VERSION ""

NS_ :

BS_:

BU_: XXX

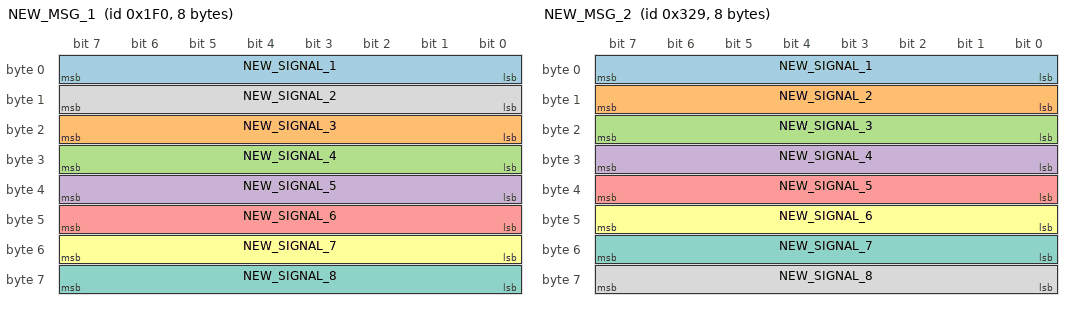
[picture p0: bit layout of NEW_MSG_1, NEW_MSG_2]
BO_ 496 NEW_MSG_1: 8 XXX
 SG_ NEW_SIGNAL_1 : 0|8@1+ (1,0) [0|255] "" XXX
 SG_ NEW_SIGNAL_3 : 23|8@0+ (1,0) [0|255] "" XXX
 SG_ NEW_SIGNAL_4 : 31|8@0+ (1,0) [0|255] "" XXX
 SG_ NEW_SIGNAL_5 : 39|8@0+ (1,0) [0|255] "" XXX
 SG_ NEW_SIGNAL_6 : 47|8@0+ (1,0) [0|255] "" XXX
 SG_ NEW_SIGNAL_7 : 55|8@0+ (1,0) [0|255] "" XXX
 SG_ NEW_SIGNAL_8 : 63|8@0+ (1,0) [0|255] "" XXX
 SG_ NEW_SIGNAL_2 : 15|8@0+ (1,0) [0|255] "" XXX

BO_ 809 NEW_MSG_2: 8 XXX
 SG_ NEW_SIGNAL_1 : 7|8@0+ (1,0) [0|255] "" XXX
 SG_ NEW_SIGNAL_2 : 15|8@0+ (1,0) [0|255] "" XXX
 SG_ NEW_SIGNAL_3 : 23|8@0+ (1,0) [0|255] "" XXX
 SG_ NEW_SIGNAL_4 : 31|8@0+ (1,0) [0|255] "" XXX
 SG_ NEW_SIGNAL_5 : 39|8@0+ (1,0) [0|255] "" XXX
 SG_ NEW_SIGNAL_6 : 47|8@0+ (1,0) [0|255] "" XXX
 SG_ NEW_SIGNAL_7 : 55|8@0+ (1,0) [0|255] "" XXX
 SG_ NEW_SIGNAL_8 : 63|8@0+ (1,0) [0|255] "" XXX

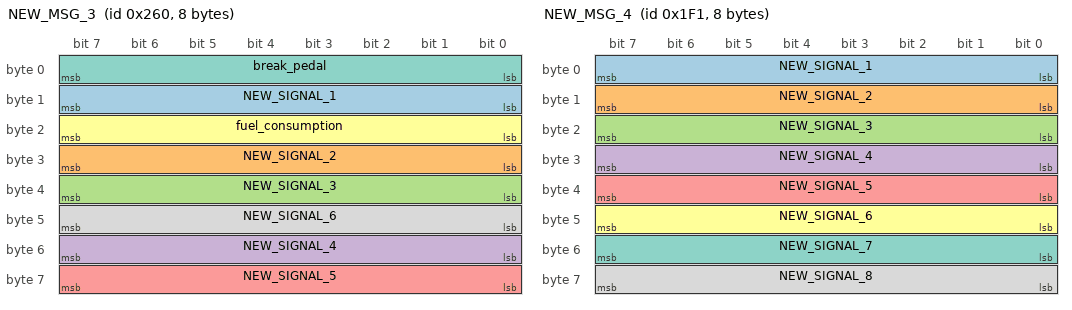
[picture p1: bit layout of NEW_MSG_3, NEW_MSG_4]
BO_ 608 NEW_MSG_3: 8 XXX
 SG_ NEW_SIGNAL_1 : 8|8@1+ (1,0) [0|255] "" XXX
 SG_ NEW_SIGNAL_2 : 31|8@0+ (1,0) [0|255] "" XXX
 SG_ NEW_SIGNAL_3 : 39|8@0+ (1,0) [0|255] "" XXX
 SG_ NEW_SIGNAL_4 : 55|8@0+ (1,0) [0|255] "" XXX
 SG_ NEW_SIGNAL_5 : 63|8@0+ (1,0) [0|255] "" XXX
 SG_ fuel_consumption : 23|8@0+ (1,0) [0|255] "" XXX
 SG_ break_pedal : 0|8@1+ (1,0) [0|255] "" XXX
 SG_ NEW_SIGNAL_6 : 47|8@0+ (1,0) [0|255] "" XXX

BO_ 497 NEW_MSG_4: 8 XXX
 SG_ NEW_SIGNAL_1 : 7|8@0+ (1,0) [0|255] "" XXX
 SG_ NEW_SIGNAL_2 : 15|8@0+ (1,0) [0|255] "" XXX
 SG_ NEW_SIGNAL_3 : 23|8@0+ (1,0) [0|255] "" XXX
 SG_ NEW_SIGNAL_4 : 31|8@0+ (1,0) [0|255] "" XXX
 SG_ NEW_SIGNAL_5 : 39|8@0+ (1,0) [0|255] "" XXX
 SG_ NEW_SIGNAL_6 : 47|8@0+ (1,0) [0|255] "" XXX
 SG_ NEW_SIGNAL_7 : 55|8@0+ (1,0) [0|255] "" XXX
 SG_ NEW_SIGNAL_8 : 63|8@0+ (1,0) [0|255] "" XXX

BO_ 1087 NEW_MSG_5: 8 XXX
 SG_ NEW_SIGNAL_1 : 23|8@0+ (1,0) [0|255] "" XXX
 SG_ NEW_SIGNAL_2 : 31|8@0+ (1,0) [0|255] "" XXX
 SG_ NEW_SIGNAL_3 : 39|8@0+ (1,0) [0|255] "" XXX
 SG_ NEW_SIGNAL_4 : 47|8@0+ (1,0) [0|255] "" XXX
 SG_ NEW_SIGNAL_5 : 39|8@0+ (1,0) [0|255] "" XXX
 SG_ NEW_SIGNAL_6 : 47|8@0+ (1,0) [0|255] "" XXX
 SG_ NEW_SIGNAL_7 : 55|8@0+ (1,0) [0|255] "" XXX
 SG_ NEW_SIGNAL_8 : 63|8@0+ (1,0) [0|255] "" XXX
 SG_ NEW_SIGNAL_9 : 7|8@0+ (1,0) [0|255] "" XXX
 SG_ NEW_SIGNAL_10 : 15|8@0+ (1,0) [0|255] "" XXX

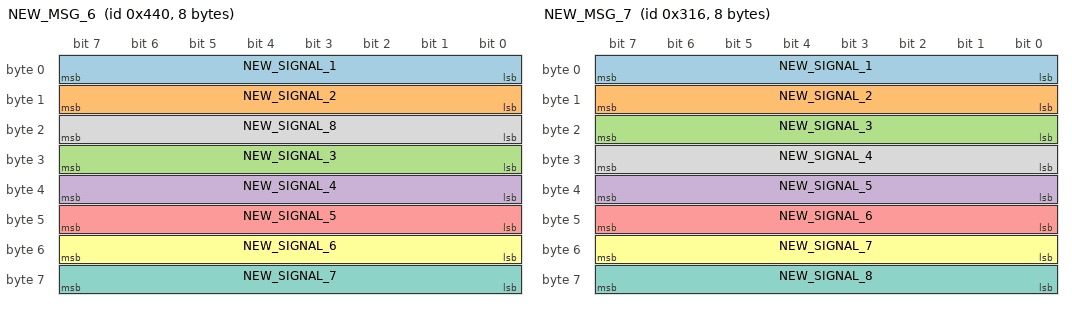
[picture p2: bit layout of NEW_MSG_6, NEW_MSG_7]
BO_ 1088 NEW_MSG_6: 8 XXX
 SG_ NEW_SIGNAL_1 : 7|8@0+ (1,0) [0|255] "" XXX
 SG_ NEW_SIGNAL_2 : 15|8@0+ (1,0) [0|255] "" XXX
 SG_ NEW_SIGNAL_3 : 31|8@0+ (1,0) [0|255] "" XXX
 SG_ NEW_SIGNAL_4 : 39|8@0+ (1,0) [0|255] "" XXX
 SG_ NEW_SIGNAL_5 : 47|8@0+ (1,0) [0|255] "" XXX
 SG_ NEW_SIGNAL_6 : 55|8@0+ (1,0) [0|255] "" XXX
 SG_ NEW_SIGNAL_7 : 63|8@0+ (1,0) [0|255] "" XXX
 SG_ NEW_SIGNAL_8 : 23|8@0+ (1,0) [0|255] "" XXX

BO_ 790 NEW_MSG_7: 8 XXX
 SG_ NEW_SIGNAL_1 : 7|8@0+ (1,0) [0|255] "" XXX
 SG_ NEW_SIGNAL_2 : 15|8@0+ (1,0) [0|255] "" XXX
 SG_ NEW_SIGNAL_3 : 23|8@0+ (1,0) [0|255] "" XXX
 SG_ NEW_SIGNAL_5 : 39|8@0+ (1,0) [0|255] "" XXX
 SG_ NEW_SIGNAL_6 : 47|8@0+ (1,0) [0|255] "" XXX
 SG_ NEW_SIGNAL_7 : 55|8@0+ (1,0) [0|255] "" XXX
 SG_ NEW_SIGNAL_8 : 63|8@0+ (1,0) [0|255] "" XXX
 SG_ NEW_SIGNAL_4 : 31|8@0+ (1,0) [0|255] "" XXX

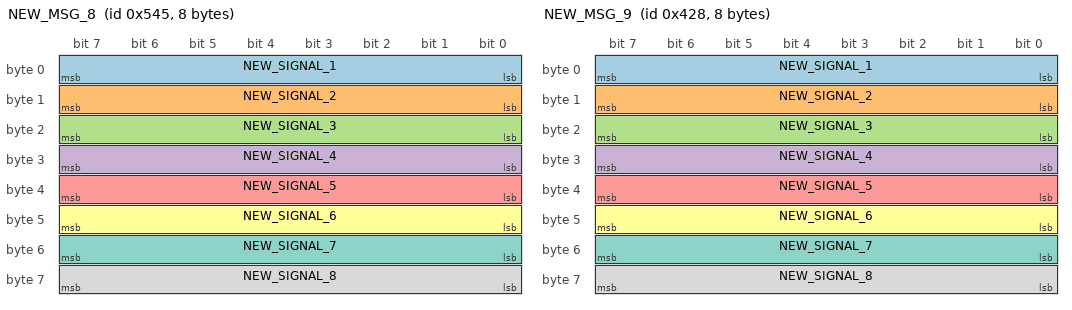
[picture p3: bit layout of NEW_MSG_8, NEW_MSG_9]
BO_ 1349 NEW_MSG_8: 8 XXX
 SG_ NEW_SIGNAL_1 : 7|8@0+ (1,0) [0|255] "" XXX
 SG_ NEW_SIGNAL_2 : 8|8@1+ (1,0) [0|65535] "" XXX
 SG_ NEW_SIGNAL_3 : 23|8@0+ (1,0) [0|255] "" XXX
 SG_ NEW_SIGNAL_4 : 31|8@0+ (1,0) [0|255] "" XXX
 SG_ NEW_SIGNAL_5 : 39|8@0+ (1,0) [0|255] "" XXX
 SG_ NEW_SIGNAL_6 : 47|8@0+ (1,0) [0|255] "" XXX
 SG_ NEW_SIGNAL_7 : 55|8@0+ (1,0) [0|255] "" XXX
 SG_ NEW_SIGNAL_8 : 63|8@0+ (1,0) [0|255] "" XXX

BO_ 1064 NEW_MSG_9: 8 XXX
 SG_ NEW_SIGNAL_1 : 7|8@0+ (1,0) [0|255] "" XXX
 SG_ NEW_SIGNAL_2 : 15|8@0+ (1,0) [0|255] "" XXX
 SG_ NEW_SIGNAL_3 : 23|8@0+ (1,0) [0|255] "" XXX
 SG_ NEW_SIGNAL_4 : 31|8@0+ (1,0) [0|255] "" XXX
 SG_ NEW_SIGNAL_5 : 39|8@0+ (1,0) [0|255] "" XXX
 SG_ NEW_SIGNAL_6 : 47|8@0+ (1,0) [0|255] "" XXX
 SG_ NEW_SIGNAL_7 : 55|8@0+ (1,0) [0|255] "" XXX
 SG_ NEW_SIGNAL_8 : 63|8@0+ (1,0) [0|255] "" XXX

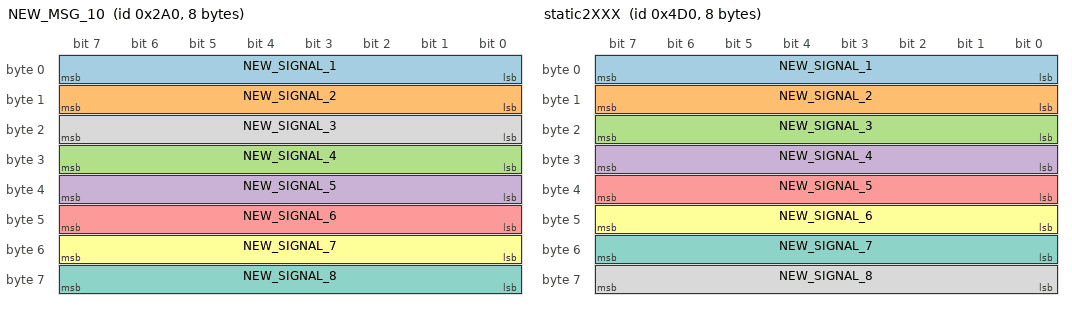
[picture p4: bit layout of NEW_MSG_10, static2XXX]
BO_ 672 NEW_MSG_10: 8 XXX
 SG_ NEW_SIGNAL_1 : 7|8@0+ (1,0) [0|255] "" XXX
 SG_ NEW_SIGNAL_2 : 15|8@0+ (1,0) [0|255] "" XXX
 SG_ NEW_SIGNAL_4 : 31|8@0+ (1,0) [0|255] "" XXX
 SG_ NEW_SIGNAL_5 : 39|8@0+ (1,0) [0|255] "" XXX
 SG_ NEW_SIGNAL_6 : 47|8@0+ (1,0) [0|255] "" XXX
 SG_ NEW_SIGNAL_7 : 55|8@0+ (1,0) [0|255] "" XXX
 SG_ NEW_SIGNAL_8 : 63|8@0+ (1,0) [0|255] "" XXX
 SG_ NEW_SIGNAL_3 : 23|8@0+ (1,0) [0|255] "" XXX

BO_ 1232 static2XXX: 8 XXX
 SG_ NEW_SIGNAL_1 : 7|8@0+ (1,0) [0|255] "" XXX
 SG_ NEW_SIGNAL_2 : 15|8@0+ (1,0) [0|255] "" XXX
 SG_ NEW_SIGNAL_3 : 23|8@0+ (1,0) [0|255] "" XXX
 SG_ NEW_SIGNAL_4 : 31|8@0+ (1,0) [0|255] "" XXX
 SG_ NEW_SIGNAL_5 : 39|8@0+ (1,0) [0|255] "" XXX
 SG_ NEW_SIGNAL_6 : 47|8@0+ (1,0) [0|255] "" XXX
 SG_ NEW_SIGNAL_7 : 55|8@0+ (1,0) [0|255] "" XXX
 SG_ NEW_SIGNAL_8 : 63|8@0+ (1,0) [0|255] "" XXX

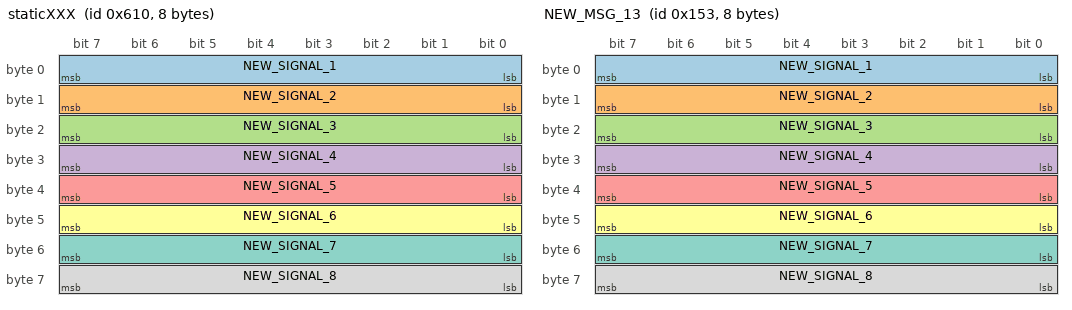
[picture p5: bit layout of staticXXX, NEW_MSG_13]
BO_ 1552 staticXXX: 8 XXX
 SG_ NEW_SIGNAL_1 : 7|8@0+ (1,0) [0|255] "" XXX
 SG_ NEW_SIGNAL_2 : 15|8@0+ (1,0) [0|255] "" XXX
 SG_ NEW_SIGNAL_3 : 23|8@0+ (1,0) [0|255] "" XXX
 SG_ NEW_SIGNAL_4 : 31|8@0+ (1,0) [0|255] "" XXX
 SG_ NEW_SIGNAL_5 : 39|8@0+ (1,0) [0|255] "" XXX
 SG_ NEW_SIGNAL_6 : 47|8@0+ (1,0) [0|255] "" XXX
 SG_ NEW_SIGNAL_7 : 55|8@0+ (1,0) [0|255] "" XXX
 SG_ NEW_SIGNAL_8 : 63|8@0+ (1,0) [0|255] "" XXX

BO_ 339 NEW_MSG_13: 8 XXX
 SG_ NEW_SIGNAL_1 : 7|8@0+ (1,0) [0|255] "" XXX
 SG_ NEW_SIGNAL_2 : 15|8@0+ (1,0) [0|255] "" XXX
 SG_ NEW_SIGNAL_3 : 23|8@0+ (1,0) [0|127] "" XXX
 SG_ NEW_SIGNAL_4 : 31|8@0+ (1,0) [0|255] "" XXX
 SG_ NEW_SIGNAL_5 : 39|8@0+ (1,0) [0|255] "" XXX
 SG_ NEW_SIGNAL_6 : 47|8@0+ (1,0) [0|255] "" XXX
 SG_ NEW_SIGNAL_7 : 55|8@0+ (1,0) [0|255] "" XXX
 SG_ NEW_SIGNAL_8 : 63|8@0+ (1,0) [0|255] "" XXX

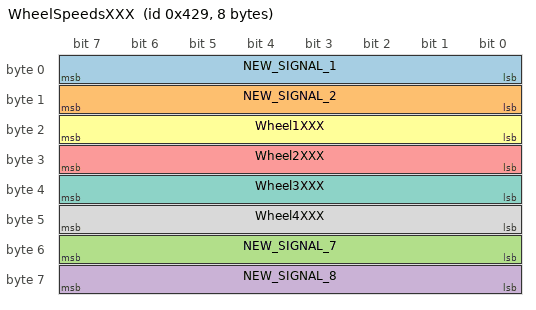
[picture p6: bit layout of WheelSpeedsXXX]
BO_ 1065 WheelSpeedsXXX: 8 XXX
 SG_ NEW_SIGNAL_1 : 7|8@0+ (1,0) [0|255] "" XXX
 SG_ NEW_SIGNAL_2 : 15|8@0+ (1,0) [0|255] "" XXX
 SG_ NEW_SIGNAL_7 : 55|8@0+ (1,0) [0|255] "" XXX
 SG_ NEW_SIGNAL_8 : 63|8@0+ (1,0) [0|255] "" XXX
 SG_ Wheel2XXX : 31|8@0+ (1,0) [0|255] "" XXX
 SG_ Wheel1XXX : 23|8@0+ (1,0) [0|127] "" XXX
 SG_ Wheel3XXX : 39|8@0+ (1,0) [0|255] "" XXX
 SG_ Wheel4XXX : 47|8@0+ (1,0) [0|255] "" XXX
